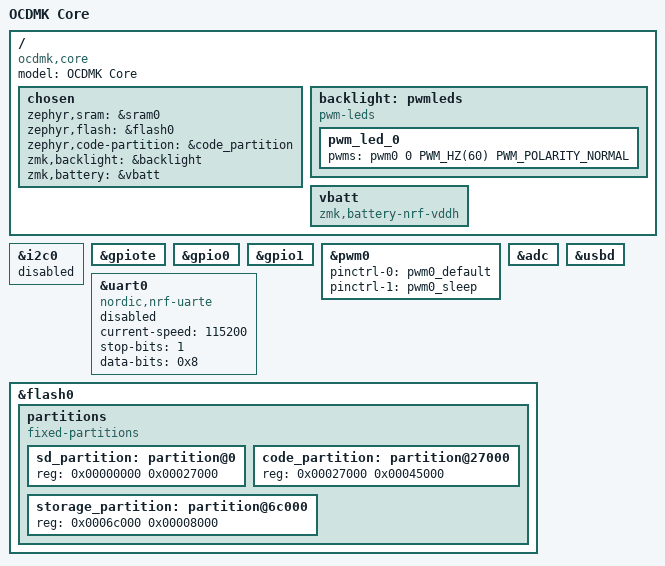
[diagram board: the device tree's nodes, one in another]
/*
 * Copyright (c) 2024 OCDMK Contributors
 *
 * SPDX-License-Identifier: MIT
 */

/dts-v1/;
#include <nordic/nrf52833_qiaa.dtsi>
#include <common/nordic/nrf52833_uf2_boot_mode.dtsi>
#include "ocdmk_core_pins.dtsi"
#include "ocdmk_core-pinctrl.dtsi"

/ {
    model = "OCDMK Core";
    compatible = "ocdmk,core";

    chosen {
        zephyr,sram = &sram0;
        zephyr,flash = &flash0;
        zephyr,code-partition = &code_partition;
        zmk,backlight = &backlight;
        zmk,battery = &vbatt;
    };

    backlight: pwmleds {
        compatible = "pwm-leds";
        pwm_led_0 {
            /* 500kHz switching frequency */
            pwms = <&pwm0 0 PWM_HZ(60) PWM_POLARITY_NORMAL>;
        };
    };
    vbatt: vbatt {
        compatible = "zmk,battery-nrf-vddh";
    };
};


&i2c0 {
    status = "disabled";
};

&gpiote {
    status = "okay";
};

&gpio0 {
    status = "okay";
};

&gpio1 {
    status = "okay";
};

&pwm0 {
    status = "okay";
    pinctrl-0 = <&pwm0_default>;
    pinctrl-1 = <&pwm0_sleep>;
    pinctrl-names = "default", "sleep";
};

/* SAADC: required for zmk,battery-nrf-vddh (VDDHDIV5 internal sense) */
&adc {
    status = "okay";
};

/*
 * UART for wired split interconnect.
 * Disabled by default; the left/right shield overlays enable it
 * (with per-side pinctrl) when building without CONFIG_ZMK_BLE.
 */
ocdmk_core_serial: &uart0 {
    compatible = "nordic,nrf-uarte";
    status = "disabled";
    current-speed = <115200>;
    stop-bits = "1";
    data-bits = <0x8>;
};



zephyr_udc0: &usbd {
    status = "okay";
};

&flash0 {
    /*
     * For more information, see:
     * http://docs.zephyrproject.org/latest/devices/dts/flash_partitions.html
     */
    partitions {
        compatible = "fixed-partitions";
        #address-cells = <1>;
        #size-cells = <1>;

        sd_partition: partition@0 {
            reg = <0x00000000 0x00027000>;
        };
        code_partition: partition@27000 {
            reg = <0x00027000 0x00045000>;
        };

        /*
         * The flash starting at 0x0006c000 and ending at
         * 0x00073fff is reserved for use by the application.
         */

        /*
         * Storage partition will be used by FCB/LittleFS/NVS
         * if enabled.
         */
        storage_partition: partition@6c000 {
            reg = <0x0006c000 0x00008000>;
        };
    };
};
